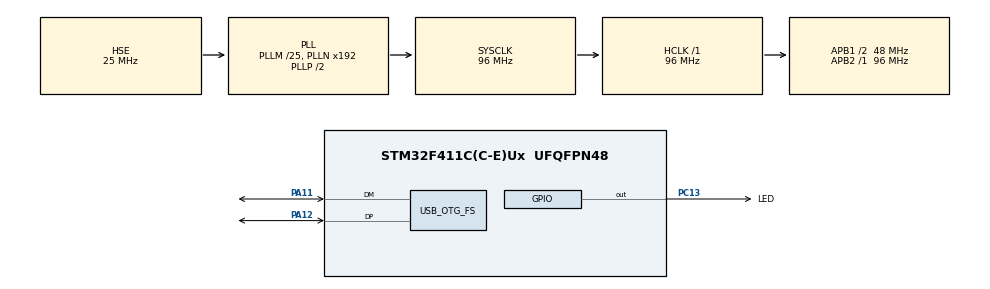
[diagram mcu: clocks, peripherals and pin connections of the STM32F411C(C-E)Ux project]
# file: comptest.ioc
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AL94.I-CUBE-USBD-COMPOSITE.1.0.0.CompositeCcUSBJjCOMPOSITEJjCDCIiACM=true
AL94.I-CUBE-USBD-COMPOSITE.1.0.0.CompositeCcUSBJjCOMPOSITEJjCOMPOSITE=true
AL94.I-CUBE-USBD-COMPOSITE.1.0.0.CompositeCcUSBJjCOMPOSITEJjCore=true
AL94.I-CUBE-USBD-COMPOSITE.1.0.0.CompositeCcUSBJjCOMPOSITEJjHIDIiCUSTOM=true
AL94.I-CUBE-USBD-COMPOSITE.1.0.0.CompositeCcUSBJjCOMPOSITEJjMSCIiBOT=true
AL94.I-CUBE-USBD-COMPOSITE.1.0.0._STM32F1_DEVICE=false
AL94.I-CUBE-USBD-COMPOSITE.1.0.0._USBD_USE_CDC_ACM=true
AL94.I-CUBE-USBD-COMPOSITE.1.0.0._USBD_USE_HID_CUSTOM=true
AL94.I-CUBE-USBD-COMPOSITE.1.0.0._USBD_USE_MSC=true
FREERTOS.Tasks01=mainTask,24,128,startMainTask,Default,NULL,Dynamic,NULL,NULL;tickTask,8,128,startTickTask,Default,NULL,Dynamic,NULL,NULL
FREERTOS.configUSE_NEWLIB_REENTRANT=1
Mcu.Family=STM32F4
Mcu.Name=STM32F411C(C-E)Ux
Mcu.Package=UFQFPN48
NVIC.OTG_FS_IRQn=true\:5\:0\:false\:false\:true\:true\:true\:true
NVIC.PriorityGroup=NVIC_PRIORITYGROUP_4
NVIC.TIM1_TRG_COM_TIM11_IRQn=true\:15\:0\:false\:false\:true\:false\:false\:true
NVIC.TimeBase=TIM1_TRG_COM_TIM11_IRQn
NVIC.TimeBaseIP=TIM11
PA11.Mode=Device_Only
PA11.Signal=USB_OTG_FS_DM
PA12.Mode=Device_Only
PA12.Signal=USB_OTG_FS_DP
PA13.Mode=Serial_Wire
PA13.Signal=SYS_JTMS-SWDIO
PA14.Mode=Serial_Wire
PA14.Signal=SYS_JTCK-SWCLK
PC13-ANTI_TAMP.GPIO_Label=LED
PC13-ANTI_TAMP.GPIO_ModeDefaultOutputPP=GPIO_MODE_OUTPUT_OD
PC13-ANTI_TAMP.PinState=GPIO_PIN_RESET
PC13-ANTI_TAMP.Signal=GPIO_Output
PH0\ -\ OSC_IN.Mode=HSE-External-Oscillator
PH0\ -\ OSC_IN.Signal=RCC_OSC_IN
PH1\ -\ OSC_OUT.Mode=HSE-External-Oscillator
PH1\ -\ OSC_OUT.Signal=RCC_OSC_OUT
ProjectManager.HeapSize=0x200
ProjectManager.StackSize=0x400
ProjectManager.TargetToolchain=STM32CubeIDE
RCC.48MHZClocksFreq_Value=48000000
RCC.AHBFreq_Value=96000000
RCC.APB1CLKDivider=RCC_HCLK_DIV2
RCC.APB1Freq_Value=48000000
RCC.APB1TimFreq_Value=96000000
RCC.APB2Freq_Value=96000000
RCC.APB2TimFreq_Value=96000000
RCC.CortexFreq_Value=96000000
RCC.HCLKFreq_Value=96000000
RCC.HSE_VALUE=25000000
RCC.HSI_VALUE=16000000
RCC.LSE_VALUE=32768
RCC.PLLM=25
RCC.SYSCLKFreq_VALUE=96000000
RCC.SYSCLKSource=RCC_SYSCLKSOURCE_PLLCLK
RCC.VCOOutputFreq_Value=192000000
USB_OTG_FS.VirtualMode=Device_Only
VP_AL94.I-CUBE-USBD-COMPOSITE_VS_USBJjComposite_1.0.0_1.0.0.Mode=USBJjComposite
VP_FREERTOS_VS_CMSIS_V2.Mode=CMSIS_V2
VP_SYS_VS_tim11.Mode=TIM11
board=custom

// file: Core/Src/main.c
/* USER CODE BEGIN Header */
/**
  ******************************************************************************
  * @file           : main.c
  * @brief          : Main program body
  ******************************************************************************
  * @attention
  *
  * <h2><center>&copy; Copyright (c) 2021 STMicroelectronics.
  * All rights reserved.</center></h2>
  *
  * This software component is licensed by ST under BSD 3-Clause license,
  * the "License"; You may not use this file except in compliance with the
  * License. You may obtain a copy of the License at:
  *                        opensource.org/licenses/BSD-3-Clause
  *
  ******************************************************************************
  */
/* USER CODE END Header */
#include "main.h"
#include "cmsis_os.h"
#include "usb_otg.h"
#include "gpio.h"

/* USER CODE BEGIN Includes */
#include "usb_device.h"
#include "usbd_cdc_acm_if.h"
/* USER CODE END Includes */

void SystemClock_Config(void);
void MX_FREERTOS_Init(void);

/* USER CODE BEGIN 0 */

int _write(int file, char *ptr, int len) {
    CDC_Transmit(0, (uint8_t *)ptr, len);
    return len;
}

/* USER CODE END 0 */

int main(void)
{

  /* MCU Configuration--------------------------------------------------------*/

  /* Reset of all peripherals, Initializes the Flash interface and the Systick. */
  HAL_Init();

  /* Configure the system clock */
  SystemClock_Config();

  /* Initialize all configured peripherals */
  MX_GPIO_Init();
  MX_USB_OTG_FS_PCD_Init();
  /* USER CODE BEGIN 2 */
  MX_USB_DEVICE_Init();
  /* USER CODE END 2 */

  /* Init scheduler */
  osKernelInitialize();  /* Call init function for freertos objects (in freertos.c) */
  MX_FREERTOS_Init();
  /* Start scheduler */
  osKernelStart();

  /* We should never get here as control is now taken by the scheduler */
  /* Infinite loop */
  /* USER CODE BEGIN WHILE */

  uint32_t now = 0, last_blink = 0;

  while (1)
  {

	  now = HAL_GetTick();

	  if (now - last_blink >= 500) {
		  HAL_GPIO_TogglePin(LED_GPIO_Port, LED_Pin);

		  last_blink = now;
	  }

    /* USER CODE END WHILE */

  }
}

void SystemClock_Config(void)
{
  RCC_OscInitTypeDef RCC_OscInitStruct = {0};
  RCC_ClkInitTypeDef RCC_ClkInitStruct = {0};

  /** Configure the main internal regulator output voltage
  */
  __HAL_RCC_PWR_CLK_ENABLE();
  __HAL_PWR_VOLTAGESCALING_CONFIG(PWR_REGULATOR_VOLTAGE_SCALE1);
  /** Initializes the RCC Oscillators according to the specified parameters
  * in the RCC_OscInitTypeDef structure.
  */
  RCC_OscInitStruct.OscillatorType = RCC_OSCILLATORTYPE_HSE;
  RCC_OscInitStruct.HSEState = RCC_HSE_ON;
  RCC_OscInitStruct.PLL.PLLState = RCC_PLL_ON;
  RCC_OscInitStruct.PLL.PLLSource = RCC_PLLSOURCE_HSE;
  RCC_OscInitStruct.PLL.PLLM = 25;
  RCC_OscInitStruct.PLL.PLLN = 192;
  RCC_OscInitStruct.PLL.PLLP = RCC_PLLP_DIV2;
  RCC_OscInitStruct.PLL.PLLQ = 4;
  if (HAL_RCC_OscConfig(&RCC_OscInitStruct) != HAL_OK)
  {
    Error_Handler();
  }
  /** Initializes the CPU, AHB and APB buses clocks
  */
  RCC_ClkInitStruct.ClockType = RCC_CLOCKTYPE_HCLK|RCC_CLOCKTYPE_SYSCLK
                              |RCC_CLOCKTYPE_PCLK1|RCC_CLOCKTYPE_PCLK2;
  RCC_ClkInitStruct.SYSCLKSource = RCC_SYSCLKSOURCE_PLLCLK;
  RCC_ClkInitStruct.AHBCLKDivider = RCC_SYSCLK_DIV1;
  RCC_ClkInitStruct.APB1CLKDivider = RCC_HCLK_DIV2;
  RCC_ClkInitStruct.APB2CLKDivider = RCC_HCLK_DIV1;

  if (HAL_RCC_ClockConfig(&RCC_ClkInitStruct, FLASH_LATENCY_3) != HAL_OK)
  {
    Error_Handler();
  }
}

void HAL_TIM_PeriodElapsedCallback(TIM_HandleTypeDef *htim)
{
  if (htim->Instance == TIM11) {
    HAL_IncTick();
  }
}

void Error_Handler(void)
{
  __disable_irq();
  while (1)
  {
  }
}

/************************ (C) COPYRIGHT STMicroelectronics *****END OF FILE****/

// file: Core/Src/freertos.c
/* USER CODE BEGIN Header */
/**
  ******************************************************************************
  * File Name          : freertos.c
  * Description        : Code for freertos applications
  ******************************************************************************
  * @attention
  *
  * <h2><center>&copy; Copyright (c) 2021 STMicroelectronics.
  * All rights reserved.</center></h2>
  *
  * This software component is licensed by ST under Ultimate Liberty license
  * SLA0044, the "License"; You may not use this file except in compliance with
  * the License. You may obtain a copy of the License at:
  *                             www.st.com/SLA0044
  *
  ******************************************************************************
  */
/* USER CODE END Header */

#include "FreeRTOS.h"
#include "task.h"
#include "main.h"
#include "cmsis_os.h"

/* Definitions for mainTask */
osThreadId_t mainTaskHandle;
const osThreadAttr_t mainTask_attributes = {
  .name = "mainTask",
  .stack_size = 128 * 4,
  .priority = (osPriority_t) osPriorityNormal,
};
/* Definitions for tickTask */
osThreadId_t tickTaskHandle;
const osThreadAttr_t tickTask_attributes = {
  .name = "tickTask",
  .stack_size = 128 * 4,
  .priority = (osPriority_t) osPriorityLow,
};

void startMainTask(void *argument);
void startTickTask(void *argument);

void MX_FREERTOS_Init(void); /* (MISRA C 2004 rule 8.1) */

void MX_FREERTOS_Init(void) {

  /* Create the thread(s) */
  /* creation of mainTask */
  mainTaskHandle = osThreadNew(startMainTask, NULL, &mainTask_attributes);

  /* creation of tickTask */
  tickTaskHandle = osThreadNew(startTickTask, NULL, &tickTask_attributes);

}

void startMainTask(void *argument)
{
  for(;;)
  {
    osDelay(1);
  }
}

void startTickTask(void *argument)
{
  /* USER CODE BEGIN startTickTask */
  /* Infinite loop */
  for(;;)
  {
	DBG("Tick %lu", osKernelGetTickCount() / 1000);
    osDelay(1000);
  }
  /* USER CODE END startTickTask */
}

/************************ (C) COPYRIGHT STMicroelectronics *****END OF FILE****/
